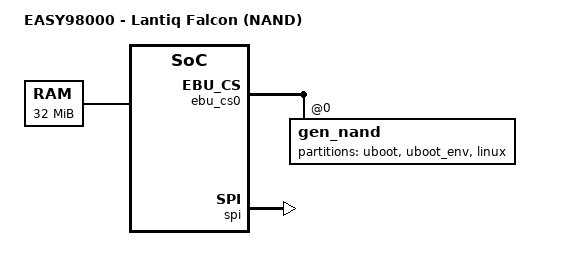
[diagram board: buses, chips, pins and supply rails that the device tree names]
/dts-v1/;

/include/ "falcon.dtsi"

/ {
	model = "EASY98000 - Lantiq Falcon (NAND)";
	compatible = "lantiq,falcon-easy98000-nand", "lantiq,falcon-easy98000", "lantiq,falcon";

	chosen {
		bootargs-append = "console=ttyLTQ0,115200 init=/etc/preinit";
	};

	memory@0 {
		reg = <0x0 0x2000000>;
	};
};

&ebu_cs0 {
	gen_nand@0 {
		compatible = "gen_nand", "lantiq,nand-falcon";
		bank-width = <1>;
		reg = <0x0 0x40000>;
		#address-cells = <1>;
		#size-cells = <1>;
		linux,mtd-name = "gen_nand";
		bbt-use-flash;

		partition@0 {
			label = "uboot";
			reg = <0x00000 0x40000>;
		};

		partition@10000 {
			label = "uboot_env";
			reg = <0x40000 0x40000>;
		};

		partition@20000 {
			label = "linux";
			reg = <0x80000 0x3d0000>;
		};
	};
};

&spi {
	status = "okay";
};
